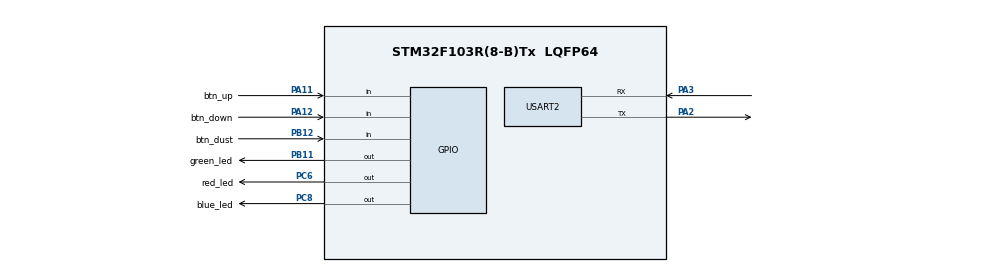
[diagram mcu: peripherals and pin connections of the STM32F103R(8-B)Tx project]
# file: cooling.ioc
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Mcu.Family=STM32F1
Mcu.Name=STM32F103R(8-B)Tx
Mcu.Package=LQFP64
NVIC.PriorityGroup=NVIC_PRIORITYGROUP_4
PA11.GPIO_Label=btn_up
PA11.GPIO_PuPd=GPIO_PULLUP
PA11.Signal=GPIO_Input
PA12.GPIO_Label=btn_down
PA12.GPIO_PuPd=GPIO_PULLUP
PA12.Signal=GPIO_Input
PA2.Mode=Asynchronous
PA2.Signal=USART2_TX
PA3.Mode=Asynchronous
PA3.Signal=USART2_RX
PB11.GPIO_Label=green_led
PB11.Signal=GPIO_Output
PB12.GPIO_Label=btn_dust
PB12.GPIO_PuPd=GPIO_PULLUP
PB12.Signal=GPIO_Input
PC6.GPIO_Label=red_led
PC6.Signal=GPIO_Output
PC8.GPIO_Label=blue_led
PC8.Signal=GPIO_Output
ProjectManager.HeapSize=0x200
ProjectManager.StackSize=0x400
ProjectManager.TargetToolchain=STM32CubeIDE
RCC.APB1Freq_Value=8000000
RCC.APB2Freq_Value=8000000
USART2.VirtualMode=VM_ASYNC
VP_SYS_VS_ND.Mode=No_Debug
board=custom

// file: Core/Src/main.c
/* USER CODE BEGIN Header */
/**
  ******************************************************************************
  * @file           : main.c
  * @brief          : Main program body
  ******************************************************************************
  * @attention
  *
  * <h2><center>&copy; Copyright (c) 2020 STMicroelectronics.
  * All rights reserved.</center></h2>
  *
  * This software component is licensed by ST under BSD 3-Clause license,
  * the "License"; You may not use this file except in compliance with the
  * License. You may obtain a copy of the License at:
  *                        opensource.org/licenses/BSD-3-Clause
  *
  ******************************************************************************
  */
/* USER CODE END Header */
#include "main.h"
#include "usart.h"
#include "gpio.h"

void SystemClock_Config(void);
/* USER CODE BEGIN PFP */
int _read(int file, char *ptr, int len);
int _write(int file, char *ptr, int len);
/* USER CODE END PFP */

int main(void)
{

  /* MCU Configuration--------------------------------------------------------*/

  /* Reset of all peripherals, Initializes the Flash interface and the Systick. */
  HAL_Init();

  /* Configure the system clock */
  SystemClock_Config();

  /* Initialize all configured peripherals */
  MX_GPIO_Init();
  MX_USART2_UART_Init();

  /* Infinite loop */
  /* USER CODE BEGIN WHILE */
  	uint8_t buf[10] = "\n\r";
  	uint8_t current_temp = 20;
  	uint8_t dust = 10;
    uint8_t low, high;
    uint8_t up_btn_state, down_btn_state, dust_btn_state;

    printf("Input low temperature >> ");
    scanf("%s", buf);
    printf("\n\r");
    low = (uint8_t)atoi(buf);
    printf("Input high temperature >> ");
    scanf("%s", buf);
    printf("\n\r");
    high = (uint8_t)atoi(buf);

    while (1)
    {
    	up_btn_state = HAL_GPIO_ReadPin(GPIOA, btn_up_Pin);
    	down_btn_state = HAL_GPIO_ReadPin(GPIOA, btn_down_Pin);
    	dust_btn_state = HAL_GPIO_ReadPin(btn_dust_GPIO_Port, btn_dust_Pin);

    	if(!up_btn_state || !down_btn_state || !dust_btn_state){
			if(!up_btn_state){
				current_temp++;
			}
			if(!down_btn_state){
				current_temp--;
			}
			if(!dust_btn_state){
				dust++;
			}
			printf("Current state(high/low/current/dust) : (%d/%d/%d/%d)\n\r",
					high, low, current_temp, dust);
			HAL_Delay(300);
    	}

		if(current_temp <= low){
			HAL_GPIO_WritePin(GPIOC, red_led_Pin, 1);
			HAL_GPIO_WritePin(GPIOC, blue_led_Pin, 0);
		}
		else if(current_temp >= high){
			HAL_GPIO_WritePin(GPIOC, red_led_Pin, 0);
			HAL_GPIO_WritePin(GPIOC, blue_led_Pin, 1);
		}
		else{
			HAL_GPIO_WritePin(GPIOC, red_led_Pin, 0);
			HAL_GPIO_WritePin(GPIOC, blue_led_Pin, 0);
		}
		if(dust <= 20){
			HAL_GPIO_WritePin(green_led_GPIO_Port, green_led_Pin, 1);
		}
		else{
			HAL_GPIO_WritePin(green_led_GPIO_Port, green_led_Pin, 0);
		}
    }
  /* USER CODE END 3 */
}

void SystemClock_Config(void)
{
  RCC_OscInitTypeDef RCC_OscInitStruct = {0};
  RCC_ClkInitTypeDef RCC_ClkInitStruct = {0};

  /** Initializes the RCC Oscillators according to the specified parameters
  * in the RCC_OscInitTypeDef structure.
  */
  RCC_OscInitStruct.OscillatorType = RCC_OSCILLATORTYPE_HSI;
  RCC_OscInitStruct.HSIState = RCC_HSI_ON;
  RCC_OscInitStruct.HSICalibrationValue = RCC_HSICALIBRATION_DEFAULT;
  RCC_OscInitStruct.PLL.PLLState = RCC_PLL_NONE;
  if (HAL_RCC_OscConfig(&RCC_OscInitStruct) != HAL_OK)
  {
    Error_Handler();
  }
  /** Initializes the CPU, AHB and APB buses clocks
  */
  RCC_ClkInitStruct.ClockType = RCC_CLOCKTYPE_HCLK|RCC_CLOCKTYPE_SYSCLK
                              |RCC_CLOCKTYPE_PCLK1|RCC_CLOCKTYPE_PCLK2;
  RCC_ClkInitStruct.SYSCLKSource = RCC_SYSCLKSOURCE_HSI;
  RCC_ClkInitStruct.AHBCLKDivider = RCC_SYSCLK_DIV1;
  RCC_ClkInitStruct.APB1CLKDivider = RCC_HCLK_DIV1;
  RCC_ClkInitStruct.APB2CLKDivider = RCC_HCLK_DIV1;

  if (HAL_RCC_ClockConfig(&RCC_ClkInitStruct, FLASH_LATENCY_0) != HAL_OK)
  {
    Error_Handler();
  }
}

/* USER CODE BEGIN 4 */
int _read(int file, char *ptr, int len){
	HAL_UART_Receive(&huart2, (uint8_t *)ptr, 1, 0xFFFF);
	HAL_UART_Transmit(&huart2, (uint8_t *)ptr, 1, 100);
	return 1;
}

int _write(int file, char *ptr, int len){
	HAL_UART_Transmit(&huart2, (uint8_t *)ptr, len, 100);
	return len;
}
/* USER CODE END 4 */

void Error_Handler(void)
{
}

/************************ (C) COPYRIGHT STMicroelectronics *****END OF FILE****/
